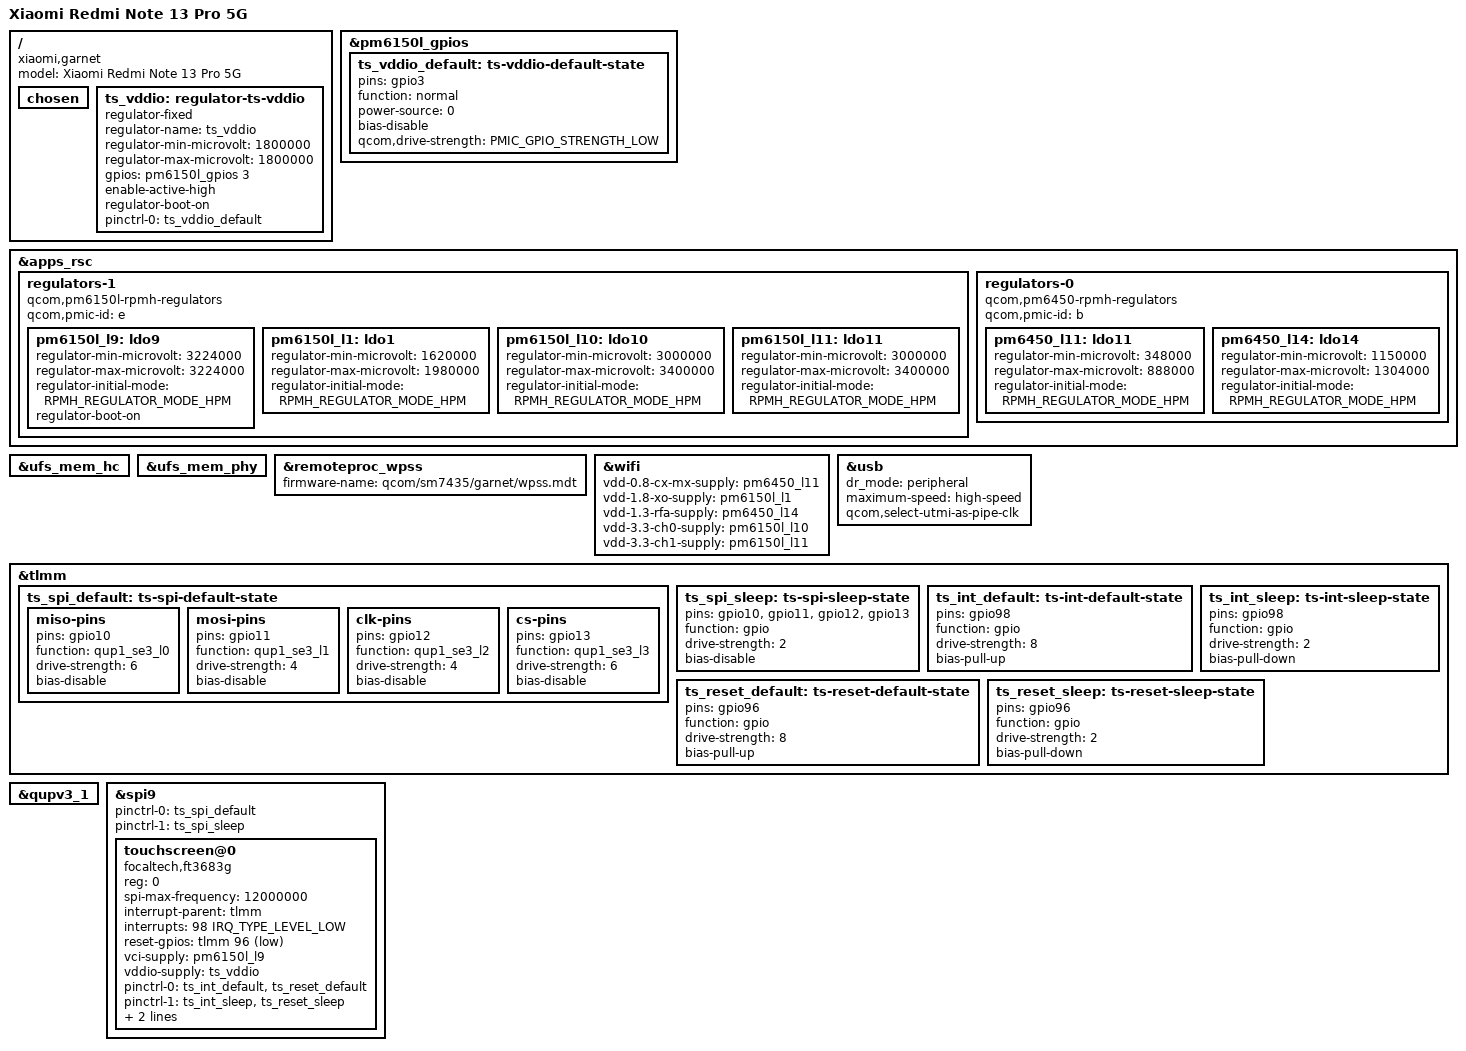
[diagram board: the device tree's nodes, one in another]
// SPDX-License-Identifier: BSD-3-Clause
/*
 * Xiaomi Redmi Note 13 Pro 5G / POCO X6 5G (garnet)
 *
 * Boots via Mu-Silicium UEFI (EFI stub), display via GOP framebuffer.
 * Also brings up the embedded UFS device and the dwc3 controller in
 * peripheral mode, high-speed only (the SS/QMP PHY is not initialised by
 * Linux yet).
 */

/dts-v1/;

#include <dt-bindings/gpio/gpio.h>
#include <dt-bindings/interrupt-controller/irq.h>
#include <dt-bindings/pinctrl/qcom,pmic-gpio.h>
#include <dt-bindings/regulator/qcom,rpmh-regulator.h>

#include "sm7435.dtsi"
#include "pm6150l.dtsi"

/ {
	model = "Xiaomi Redmi Note 13 Pro 5G";
	compatible = "xiaomi,garnet", "qcom,sm7435";

	chosen {
		/* Kernel cmdline comes from the bootloader entry (systemd-boot) */
	};

	/*
	 * Touchscreen iovdd.  Downstream this is a fixed 1.8 V regulator
	 * switched by PM6150L GPIO3 (enable-active-high, boot-on).  The
	 * PMIC is only reachable through SPMI, which is described in
	 * sm7435.dtsi; without it this rail is never actually enabled and
	 * the FT3683G stays silent (MISO idle high, every read 0xffff).
	 */
	ts_vddio: regulator-ts-vddio {
		compatible = "regulator-fixed";
		regulator-name = "ts_vddio";
		regulator-min-microvolt = <1800000>;
		regulator-max-microvolt = <1800000>;
		gpios = <&pm6150l_gpios 3 GPIO_ACTIVE_HIGH>;
		enable-active-high;
		regulator-boot-on;
		pinctrl-names = "default";
		pinctrl-0 = <&ts_vddio_default>;
	};
};

&pm6150l_gpios {
	/* PM6150L VIN1 is the 1.8 V rail on this board */
	ts_vddio_default: ts-vddio-default-state {
		pins = "gpio3";
		function = "normal";
		power-source = <0>;
		bias-disable;
		qcom,drive-strength = <PMIC_GPIO_STRENGTH_LOW>;
	};
};

/*
 * The touchscreen avdd is PM6150L LDO9 ("ldoe9" in the stock DTB), fixed
 * at 3.224 V.  This is an RPMh-controlled regulator, hence the node sits
 * below the apps RSC.  L9 also feeds the SD card slot, so keep the same
 * voltage the stock firmware uses.
 */
&apps_rsc {
	regulators-1 {
		compatible = "qcom,pm6150l-rpmh-regulators";
		qcom,pmic-id = "e";

		pm6150l_l9: ldo9 {
			regulator-min-microvolt = <3224000>;
			regulator-max-microvolt = <3224000>;
			regulator-initial-mode = <RPMH_REGULATOR_MODE_HPM>;
			regulator-boot-on;
		};

		/* WiFi/BT: 1.8 V XO and the two 3.3 V PA/channel rails */
		pm6150l_l1: ldo1 {
			regulator-min-microvolt = <1620000>;
			regulator-max-microvolt = <1980000>;
			regulator-initial-mode = <RPMH_REGULATOR_MODE_HPM>;
		};

		pm6150l_l10: ldo10 {
			regulator-min-microvolt = <3000000>;
			regulator-max-microvolt = <3400000>;
			regulator-initial-mode = <RPMH_REGULATOR_MODE_HPM>;
		};

		pm6150l_l11: ldo11 {
			regulator-min-microvolt = <3000000>;
			regulator-max-microvolt = <3400000>;
			regulator-initial-mode = <RPMH_REGULATOR_MODE_HPM>;
		};
	};

	regulators-0 {
		compatible = "qcom,pm6450-rpmh-regulators";
		qcom,pmic-id = "b";

		/* WiFi CX/MX */
		pm6450_l11: ldo11 {
			regulator-min-microvolt = <348000>;
			regulator-max-microvolt = <888000>;
			regulator-initial-mode = <RPMH_REGULATOR_MODE_HPM>;
		};

		/* WiFi 1.3 V RFA */
		pm6450_l14: ldo14 {
			regulator-min-microvolt = <1150000>;
			regulator-max-microvolt = <1304000>;
			regulator-initial-mode = <RPMH_REGULATOR_MODE_HPM>;
		};
	};
};

/*
 * UFS: the device stores the rootfs on an embedded UFS device, the stock
 * device tree enables both the host controller and the QMP PHY.
 */
&ufs_mem_hc {
	status = "ok";
};

&ufs_mem_phy {
	status = "ok";
};

/*
 * WPSS runs the WiFi firmware.  Put the split firmware (wpss.mdt +
 * wpss.bNN) from the vendor partition in
 * /lib/firmware/qcom/sm7435/garnet/.
 */
&remoteproc_wpss {
	firmware-name = "qcom/sm7435/garnet/wpss.mdt";
	status = "okay";
};

&wifi {
	vdd-0.8-cx-mx-supply = <&pm6450_l11>;
	vdd-1.8-xo-supply = <&pm6150l_l1>;
	vdd-1.3-rfa-supply = <&pm6450_l14>;
	vdd-3.3-ch0-supply = <&pm6150l_l10>;
	vdd-3.3-ch1-supply = <&pm6150l_l11>;

	status = "okay";
};

&usb {
	status = "okay";
	dr_mode = "peripheral";
	maximum-speed = "high-speed";
	/* no SS PHY driver: don't wait for the pipe clock */
	qcom,select-utmi-as-pipe-clk;
};

&tlmm {
	ts_spi_default: ts-spi-default-state {
		miso-pins {
			pins = "gpio10";
			function = "qup1_se3_l0";
			drive-strength = <6>;
			bias-disable;
		};

		mosi-pins {
			pins = "gpio11";
			function = "qup1_se3_l1";
			drive-strength = <4>;
			bias-disable;
		};

		clk-pins {
			pins = "gpio12";
			function = "qup1_se3_l2";
			drive-strength = <4>;
			bias-disable;
		};

		cs-pins {
			pins = "gpio13";
			function = "qup1_se3_l3";
			drive-strength = <6>;
			bias-disable;
		};
	};

	ts_spi_sleep: ts-spi-sleep-state {
		pins = "gpio10", "gpio11", "gpio12", "gpio13";
		function = "gpio";
		drive-strength = <2>;
		bias-disable;
	};

	/* the GPIOs are requested by the touchscreen driver */
	ts_int_default: ts-int-default-state {
		pins = "gpio98";
		function = "gpio";
		drive-strength = <8>;
		bias-pull-up;
	};

	ts_reset_default: ts-reset-default-state {
		pins = "gpio96";
		function = "gpio";
		drive-strength = <8>;
		bias-pull-up;
	};

	ts_int_sleep: ts-int-sleep-state {
		pins = "gpio98";
		function = "gpio";
		drive-strength = <2>;
		bias-pull-down;
	};

	ts_reset_sleep: ts-reset-sleep-state {
		pins = "gpio96";
		function = "gpio";
		drive-strength = <2>;
		bias-pull-down;
	};
};

&qupv3_1 {
	status = "okay";
};

&spi9 {
	status = "okay";

	/*
	 * The serial engine has its FIFO interface fused off ("FIFO mode
	 * disabled" in dmesg), so FIFO mode can never work: transfers have to
	 * go through GPI DMA (dmas/dma-names come from sm7435.dtsi).
	 */

	pinctrl-names = "default", "sleep";
	pinctrl-0 = <&ts_spi_default>;
	pinctrl-1 = <&ts_spi_sleep>;

	/*
	 * FocalTech FT3683G on the same bus/pins as the Goodix GT9916S that
	 * other garnet panels use (downstream lists both under one node).
	 *
	 * The in-tree series driver reports plain pixels: 1220x2712.
	 *
	 * Interrupt and reset polarity are the ones the vendor driver uses
	 * (downstream: interrupts = <98 IRQ_TYPE_LEVEL_LOW>,
	 * focaltech,reset-gpio = <&tlmm 96 0x00>).
	 *
	 * "vci" is downstream's avdd (PM6150L L9E, 3.224 V); "vddio" is the
	 * 1.8 V rail switched by PM6150L GPIO3.
	 */
	touchscreen@0 {
		compatible = "focaltech,ft3683g";
		reg = <0>;
		spi-max-frequency = <12000000>;

		interrupt-parent = <&tlmm>;
		interrupts = <98 IRQ_TYPE_LEVEL_LOW>;
		reset-gpios = <&tlmm 96 GPIO_ACTIVE_LOW>;

		vci-supply = <&pm6150l_l9>;
		vddio-supply = <&ts_vddio>;

		pinctrl-names = "default", "sleep";
		pinctrl-0 = <&ts_int_default>, <&ts_reset_default>;
		pinctrl-1 = <&ts_int_sleep>, <&ts_reset_sleep>;

		touchscreen-size-x = <1220>;
		touchscreen-size-y = <2712>;
	};
};
